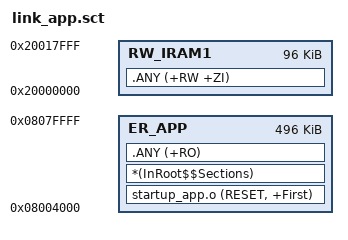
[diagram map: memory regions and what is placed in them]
; ============================================================================
; Bootloader-Everywhere 测试 APP 的链接脚本
;
; 关键：整个镜像从 0x08004000 开始（BL_APP_BASE），
;       长度上限 496KB（= BL_APP_SIZE，S1-S7）。
;       一旦超了，armlink 会直接报区域超限（L6220E / L6406E）—— 不用等上板才发现。
; ============================================================================

LR_APP 0x08004000 0x0007C000 {
    ER_APP 0x08004000 0x0007C000 {
        startup_app.o (RESET, +First)
        *(InRoot$$Sections)
        .ANY (+RO)
    }

    RW_IRAM1 0x20000000 0x00018000 {
        .ANY (+RW +ZI)
    }
}
